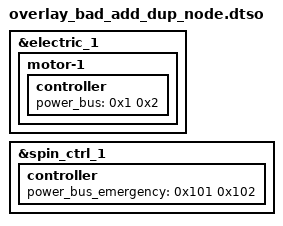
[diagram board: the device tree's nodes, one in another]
// SPDX-License-Identifier: GPL-2.0
/dts-v1/;
/plugin/;

/*
 * &electric_1/motor-1 and &spin_ctrl_1 are the same node:
 *   /testcase-data-2/substation@100/motor-1
 *
 * Thus the new node "controller" in each fragment will
 * result in an attempt to add the same node twice.
 * This will result in an error and the overlay apply
 * will fail.
 */

&electric_1 {

	motor-1 {
		controller {
			power_bus = < 0x1 0x2 >;
		};
	};
};

&spin_ctrl_1 {
		controller {
			power_bus_emergency = < 0x101 0x102 >;
		};
};
